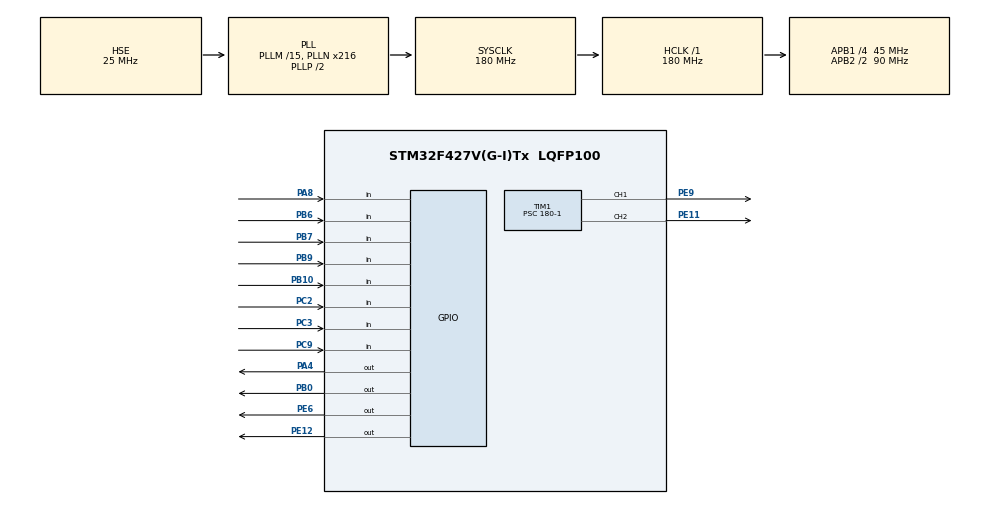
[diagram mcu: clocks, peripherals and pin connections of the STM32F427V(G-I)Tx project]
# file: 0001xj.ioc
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Mcu.Family=STM32F4
Mcu.Name=STM32F427V(G-I)Tx
Mcu.Package=LQFP100
NVIC.PriorityGroup=NVIC_PRIORITYGROUP_4
NVIC.TIM6_DAC_IRQn=true\:0\:0\:false\:false\:true\:true\:true\:true
PA13.Mode=Serial_Wire
PA13.Signal=SYS_JTMS-SWDIO
PA14.Mode=Serial_Wire
PA14.Signal=SYS_JTCK-SWCLK
PA4.Signal=GPIO_Output
PA8.Signal=GPIO_Input
PB0.Signal=GPIO_Output
PB10.Signal=GPIO_Input
PB6.Signal=GPIO_Input
PB7.Signal=GPIO_Input
PB9.Signal=GPIO_Input
PC2.Signal=GPIO_Input
PC3.Signal=GPIO_Input
PC9.Signal=GPIO_Input
PE11.Signal=S_TIM1_CH2
PE12.Signal=GPIO_Output
PE6.Signal=GPIO_Output
PE9.Signal=S_TIM1_CH1
PH0/OSC_IN.Mode=HSE-External-Clock-Source
PH0/OSC_IN.Signal=RCC_OSC_IN
PH1/OSC_OUT.Mode=HSE-External-Clock-Source
PH1/OSC_OUT.Signal=RCC_OSC_OUT
ProjectManager.HeapSize=0x200
ProjectManager.StackSize=0x400
ProjectManager.TargetToolchain=Makefile
RCC.48MHZClocksFreq_Value=90000000
RCC.AHBFreq_Value=180000000
RCC.APB1CLKDivider=RCC_HCLK_DIV4
RCC.APB1Freq_Value=45000000
RCC.APB1TimFreq_Value=90000000
RCC.APB2CLKDivider=RCC_HCLK_DIV2
RCC.APB2Freq_Value=90000000
RCC.APB2TimFreq_Value=180000000
RCC.CortexFreq_Value=180000000
RCC.HCLKFreq_Value=180000000
RCC.HSE_VALUE=25000000
RCC.HSI_VALUE=16000000
RCC.LSE_VALUE=32768
RCC.PLLM=15
RCC.PLLN=216
RCC.PLLSourceVirtual=RCC_PLLSOURCE_HSE
RCC.SYSCLKFreq_VALUE=180000000
RCC.SYSCLKSource=RCC_SYSCLKSOURCE_PLLCLK
RCC.VCOOutputFreq_Value=360000000
SH.S_TIM1_CH1.0=TIM1_CH1,PWM Generation1 CH1
SH.S_TIM1_CH2.0=TIM1_CH2,PWM Generation2 CH2
TIM1.Channel-PWM\ Generation1\ CH1=TIM_CHANNEL_1
TIM1.Channel-PWM\ Generation2\ CH2=TIM_CHANNEL_2
TIM1.Period=1000-1
TIM1.Prescaler=180-1
TIM6.Period=1000-1
TIM6.Prescaler=180-1
VP_TIM1_VS_ClockSourceINT.Mode=Internal
VP_TIM6_VS_ClockSourceINT.Mode=Enable_Timer
board=custom

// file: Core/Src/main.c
/* USER CODE BEGIN Header */
/**
  ******************************************************************************
  * @file           : main.c
  * @brief          : Main program body
  ******************************************************************************
  * @attention
  *
  * Copyright (c) 2026 STMicroelectronics.
  * All rights reserved.
  *
  * This software is licensed under terms that can be found in the LICENSE file
  * in the root directory of this software component.
  * If no LICENSE file comes with this software, it is provided AS-IS.
  *
  ******************************************************************************
  */
/* USER CODE END Header */
#include "main.h"
#include "tim.h"
#include "gpio.h"

/* USER CODE BEGIN Includes */
#include "motor.h"
#include "pid.h"
#include "huidu.h"
int temp;
// MOTOR motor[2];
/* USER CODE END Includes */

void SystemClock_Config(void);

int main(void)
{

  /* MCU Configuration--------------------------------------------------------*/

  /* Reset of all peripherals, Initializes the Flash interface and the Systick. */
  HAL_Init();

  /* Configure the system clock */
  SystemClock_Config();

  /* Initialize all configured peripherals */
  MX_GPIO_Init();
  MX_TIM1_Init();
  MX_TIM6_Init();
  /* USER CODE BEGIN 2 */
  HAL_TIM_PWM_Start(&htim1, TIM_CHANNEL_1); // PWM
  HAL_TIM_PWM_Start(&htim1, TIM_CHANNEL_2);
  // HAL_TIM_Encoder_Start(&htim2, TIM_CHANNEL_1); // 编码
  HAL_TIM_Base_Start_IT(&htim6);

  // PidInit(&(motor.pid_vel),PO SITION_PID, 9999, 1000, -9999, 100, 0, 300);
  /* USER CODE END 2 */

  /* Infinite loop */
  /* USER CODE BEGIN WHILE */
  // Set_motor(200,0);
  // Set_motor(200,1);

  float pid_p=20;
  float pid_i=0.1;
  float pid_d=35;

  PidInit(&motor[0].pid_vel, POSITION_PID, 1000, 100, 0, pid_p, pid_i, pid_d);
  PidInit(&motor[1].pid_vel, POSITION_PID, 1000, 100, 0, pid_p, pid_i, pid_d);

  while (1)
  {
    /* USER CODE END WHILE */

    /* USER CODE BEGIN 3 */

     temp = Gary_Sensor_Read_Digital();
    //  PidCalc(&(motor[0].pid_vel),temp,0);
    //  PidCalc(&(motor[1].pid_vel),temp,0);

//     if(x[0]+x[1]+x[2]==0){
//       __HAL_TIM_SET_COMPARE(&htim1, TIM_CHANNEL_1, 0);
//       __HAL_TIM_SET_COMPARE(&htim1, TIM_CHANNEL_2, 0);
//       HAL_Delay(50);
//       Set_motor(250,0);
//       Set_motor(-250,1);
//       HAL_Delay(150);
//       __HAL_TIM_SET_COMPARE(&htim1, TIM_CHANNEL_1, 0);
//       __HAL_TIM_SET_COMPARE(&htim1, TIM_CHANNEL_2, 0);
//       HAL_Delay(50);

//   }
//   else if (x[7]+x[6]+x[5]==0){
//       __HAL_TIM_SET_COMPARE(&htim1, TIM_CHANNEL_1, 0);
//       __HAL_TIM_SET_COMPARE(&htim1, TIM_CHANNEL_2, 0);
//       HAL_Delay(50);
//       Set_motor(-250,0);
//       Set_motor(250,1);
//       HAL_Delay(150);
//       __HAL_TIM_SET_COMPARE(&htim1, TIM_CHANNEL_1, 0);
//       __HAL_TIM_SET_COMPARE(&htim1, TIM_CHANNEL_2, 0);
//       HAL_Delay(50);
//   }
//   else{
//          run(motor.pid_vel.pos_out);
//   }
// }

  }
  /* USER CODE END 3 */
}

void SystemClock_Config(void)
{
  RCC_OscInitTypeDef RCC_OscInitStruct = {0};
  RCC_ClkInitTypeDef RCC_ClkInitStruct = {0};

  /** Configure the main internal regulator output voltage
  */
  __HAL_RCC_PWR_CLK_ENABLE();
  __HAL_PWR_VOLTAGESCALING_CONFIG(PWR_REGULATOR_VOLTAGE_SCALE1);

  /** Initializes the RCC Oscillators according to the specified parameters
  * in the RCC_OscInitTypeDef structure.
  */
  RCC_OscInitStruct.OscillatorType = RCC_OSCILLATORTYPE_HSE;
  RCC_OscInitStruct.HSEState = RCC_HSE_BYPASS;
  RCC_OscInitStruct.PLL.PLLState = RCC_PLL_ON;
  RCC_OscInitStruct.PLL.PLLSource = RCC_PLLSOURCE_HSE;
  RCC_OscInitStruct.PLL.PLLM = 15;
  RCC_OscInitStruct.PLL.PLLN = 216;
  RCC_OscInitStruct.PLL.PLLP = RCC_PLLP_DIV2;
  RCC_OscInitStruct.PLL.PLLQ = 4;
  if (HAL_RCC_OscConfig(&RCC_OscInitStruct) != HAL_OK)
  {
    Error_Handler();
  }

  /** Activate the Over-Drive mode
  */
  if (HAL_PWREx_EnableOverDrive() != HAL_OK)
  {
    Error_Handler();
  }

  /** Initializes the CPU, AHB and APB buses clocks
  */
  RCC_ClkInitStruct.ClockType = RCC_CLOCKTYPE_HCLK|RCC_CLOCKTYPE_SYSCLK
                              |RCC_CLOCKTYPE_PCLK1|RCC_CLOCKTYPE_PCLK2;
  RCC_ClkInitStruct.SYSCLKSource = RCC_SYSCLKSOURCE_PLLCLK;
  RCC_ClkInitStruct.AHBCLKDivider = RCC_SYSCLK_DIV1;
  RCC_ClkInitStruct.APB1CLKDivider = RCC_HCLK_DIV4;
  RCC_ClkInitStruct.APB2CLKDivider = RCC_HCLK_DIV2;

  if (HAL_RCC_ClockConfig(&RCC_ClkInitStruct, FLASH_LATENCY_5) != HAL_OK)
  {
    Error_Handler();
  }
}

void Error_Handler(void)
{
  __disable_irq();
  while (1)
  {
  }
}
